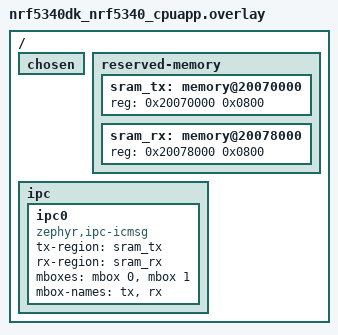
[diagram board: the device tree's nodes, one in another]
// To get started, press Ctrl+Space to bring up the completion menu and view the available nodes.

// You can also use the buttons in the sidebar to perform actions on nodes.
// Actions currently available include:

// * Enabling / disabling the node
// * Adding the bus to a bus
// * Removing the node
// * Connecting ADC channels

// For more help, browse the DeviceTree documentation at https://docs.zephyrproject.org/latest/guides/dts/index.html
// You can also visit the nRF DeviceTree extension documentation at https://nrfconnect.github.io/vscode-nrf-connect/devicetree/nrfdevicetree.html

/ {
	chosen {
		/delete-property/ zephyr,ipc_shm;
	};

	reserved-memory {
		/delete-node/ memory@20070000;

		sram_tx: memory@20070000 {
			reg = <0x20070000 0x0800>;
		};

		sram_rx: memory@20078000 {
			reg = <0x20078000 0x0800>;
		};
	};

	ipc {
		/delete-node/ ipc0;

		ipc0: ipc0 {
			compatible = "zephyr,ipc-icmsg";
			tx-region = <&sram_tx>;
			rx-region = <&sram_rx>;
			mboxes = <&mbox 0>, <&mbox 1>;
			mbox-names = "tx", "rx";
			status = "okay";
		};
	};
};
